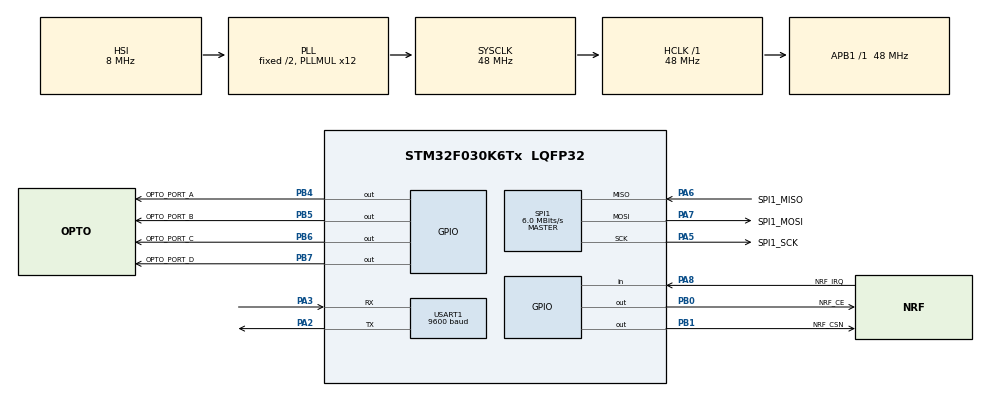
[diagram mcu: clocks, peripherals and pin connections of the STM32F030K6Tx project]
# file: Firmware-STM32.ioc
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Mcu.Family=STM32F0
Mcu.Name=STM32F030K6Tx
Mcu.Package=LQFP32
PA13.Mode=Serial_Wire
PA13.Signal=SYS_SWDIO
PA14.Mode=Serial_Wire
PA14.Signal=SYS_SWCLK
PA2.Mode=Asynchronous
PA2.Signal=USART1_TX
PA3.Mode=Asynchronous
PA3.Signal=USART1_RX
PA5.GPIO_Label=SPI1_SCK
PA5.Mode=Full_Duplex_Master
PA5.Signal=SPI1_SCK
PA6.GPIO_Label=SPI1_MISO
PA6.Mode=Full_Duplex_Master
PA6.Signal=SPI1_MISO
PA7.GPIO_Label=SPI1_MOSI
PA7.Mode=Full_Duplex_Master
PA7.Signal=SPI1_MOSI
PA8.GPIO_Label=NRF_IRQ
PA8.GPIO_PuPd=GPIO_PULLUP
PA8.Signal=GPIO_Input
PB0.GPIO_Label=NRF_CE
PB0.GPIO_ModeDefaultOutputPP=GPIO_MODE_OUTPUT_PP
PB0.GPIO_PuPd=GPIO_NOPULL
PB0.GPIO_Speed=GPIO_SPEED_FREQ_LOW
PB0.PinState=GPIO_PIN_RESET
PB0.Signal=GPIO_Output
PB1.GPIO_Label=NRF_CSN
PB1.GPIO_ModeDefaultOutputPP=GPIO_MODE_OUTPUT_PP
PB1.GPIO_PuPd=GPIO_NOPULL
PB1.GPIO_Speed=GPIO_SPEED_FREQ_LOW
PB1.PinState=GPIO_PIN_RESET
PB1.Signal=GPIO_Output
PB4.GPIO_Label=OPTO_PORT_A
PB4.GPIO_ModeDefaultOutputPP=GPIO_MODE_OUTPUT_PP
PB4.GPIO_PuPd=GPIO_NOPULL
PB4.GPIO_Speed=GPIO_SPEED_FREQ_LOW
PB4.PinState=GPIO_PIN_RESET
PB4.Signal=GPIO_Output
PB5.GPIO_Label=OPTO_PORT_B
PB5.GPIO_ModeDefaultOutputPP=GPIO_MODE_OUTPUT_PP
PB5.GPIO_PuPd=GPIO_NOPULL
PB5.GPIO_Speed=GPIO_SPEED_FREQ_LOW
PB5.PinState=GPIO_PIN_RESET
PB5.Signal=GPIO_Output
PB6.GPIO_FM6=__NULL
PB6.GPIO_Label=OPTO_PORT_C
PB6.GPIO_ModeDefaultOutputPP=GPIO_MODE_OUTPUT_PP
PB6.GPIO_PuPd=GPIO_NOPULL
PB6.GPIO_Speed=GPIO_SPEED_FREQ_LOW
PB6.PinState=GPIO_PIN_RESET
PB6.Signal=GPIO_Output
PB7.GPIO_FM7=__NULL
PB7.GPIO_Label=OPTO_PORT_D
PB7.GPIO_ModeDefaultOutputPP=GPIO_MODE_OUTPUT_PP
PB7.GPIO_PuPd=GPIO_NOPULL
PB7.GPIO_Speed=GPIO_SPEED_FREQ_LOW
PB7.PinState=GPIO_PIN_RESET
PB7.Signal=GPIO_Output
ProjectManager.HeapSize=0x200
ProjectManager.StackSize=0x400
ProjectManager.TargetToolchain=TrueSTUDIO
RCC.AHBFreq_Value=48000000
RCC.APB1Freq_Value=48000000
RCC.APB1TimFreq_Value=48000000
RCC.HCLKFreq_Value=48000000
RCC.PLLMUL=RCC_PLL_MUL12
RCC.SYSCLKFreq_VALUE=48000000
RCC.SYSCLKSource=RCC_SYSCLKSOURCE_PLLCLK
SPI1.BaudRatePrescaler=SPI_BAUDRATEPRESCALER_8
SPI1.CalculateBaudRate=6.0 MBits/s
SPI1.DataSize=SPI_DATASIZE_8BIT
SPI1.Direction=SPI_DIRECTION_2LINES
SPI1.Mode=SPI_MODE_MASTER
SPI1.NSSPMode=SPI_NSS_PULSE_DISABLE
SPI1.VirtualType=VM_MASTER
USART1.BaudRate=9600
USART1.VirtualMode-Asynchronous=VM_ASYNC
board=Firmware-STM32

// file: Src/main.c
/**
  ******************************************************************************
  * @file           : main.c
  * @brief          : Main program body
  ******************************************************************************
  ** This notice applies to any and all portions of this file
  * that are not between comment pairs USER CODE BEGIN and
  * USER CODE END. Other portions of this file, whether
  * inserted by the user or by software development tools
  * are owned by their respective copyright owners.
  *
  * COPYRIGHT(c) 2018 STMicroelectronics
  *
  * Redistribution and use in source and binary forms, with or without modification,
  * are permitted provided that the following conditions are met:
  *   1. Redistributions of source code must retain the above copyright notice,
  *      this list of conditions and the following disclaimer.
  *   2. Redistributions in binary form must reproduce the above copyright notice,
  *      this list of conditions and the following disclaimer in the documentation
  *      and/or other materials provided with the distribution.
  *   3. Neither the name of STMicroelectronics nor the names of its contributors
  *      may be used to endorse or promote products derived from this software
  *      without specific prior written permission.
  *
  * THIS SOFTWARE IS PROVIDED BY THE COPYRIGHT HOLDERS AND CONTRIBUTORS "AS IS"
  * AND ANY EXPRESS OR IMPLIED WARRANTIES, INCLUDING, BUT NOT LIMITED TO, THE
  * IMPLIED WARRANTIES OF MERCHANTABILITY AND FITNESS FOR A PARTICULAR PURPOSE ARE
  * DISCLAIMED. IN NO EVENT SHALL THE COPYRIGHT HOLDER OR CONTRIBUTORS BE LIABLE
  * FOR ANY DIRECT, INDIRECT, INCIDENTAL, SPECIAL, EXEMPLARY, OR CONSEQUENTIAL
  * DAMAGES (INCLUDING, BUT NOT LIMITED TO, PROCUREMENT OF SUBSTITUTE GOODS OR
  * SERVICES; LOSS OF USE, DATA, OR PROFITS; OR BUSINESS INTERRUPTION) HOWEVER
  * CAUSED AND ON ANY THEORY OF LIABILITY, WHETHER IN CONTRACT, STRICT LIABILITY,
  * OR TORT (INCLUDING NEGLIGENCE OR OTHERWISE) ARISING IN ANY WAY OUT OF THE USE
  * OF THIS SOFTWARE, EVEN IF ADVISED OF THE POSSIBILITY OF SUCH DAMAGE.
  *
  ******************************************************************************
  */
#include "main.h"
#include "stm32f0xx_hal.h"

/* USER CODE BEGIN Includes */
#include "receiver.h"

#include  <errno.h>
#include  <sys/unistd.h>
/* USER CODE END Includes */

SPI_HandleTypeDef hspi1;

UART_HandleTypeDef huart1;

/* USER CODE BEGIN PV */
/* Private variables ---------------------------------------------------------*/

/* USER CODE END PV */

void SystemClock_Config(void);
static void MX_GPIO_Init(void);
static void MX_SPI1_Init(void);
static void MX_USART1_UART_Init(void);

/* USER CODE BEGIN PFP */
/* Private function prototypes -----------------------------------------------*/

/* USER CODE END PFP */

/* USER CODE BEGIN 0 */

int _write(int fd, const void* data, size_t len)
{
   if ((fd != STDOUT_FILENO) && (fd != STDERR_FILENO))
   {
      errno = EBADF;
      return -1;
   }

   HAL_StatusTypeDef status = HAL_UART_Transmit(&huart1, (uint8_t*)data, len, 1000);

   return (status == HAL_OK ? len : 0);
}

/* USER CODE END 0 */

int main(void)
{

  /* MCU Configuration----------------------------------------------------------*/

  /* Reset of all peripherals, Initializes the Flash interface and the Systick. */
  HAL_Init();

  /* Configure the system clock */
  SystemClock_Config();

  /* Initialize all configured peripherals */
  MX_GPIO_Init();
  MX_SPI1_Init();
  MX_USART1_UART_Init();
  /* USER CODE BEGIN 2 */

  receiver_init(&hspi1);

  /* USER CODE END 2 */

  /* Infinite loop */
  /* USER CODE BEGIN WHILE */
  while (1)
  {
      receiver_task();
  /* USER CODE END WHILE */

  }

}

void SystemClock_Config(void)
{

  RCC_OscInitTypeDef RCC_OscInitStruct;
  RCC_ClkInitTypeDef RCC_ClkInitStruct;
  RCC_PeriphCLKInitTypeDef PeriphClkInit;

    /**Initializes the CPU, AHB and APB busses clocks
    */
  RCC_OscInitStruct.OscillatorType = RCC_OSCILLATORTYPE_HSI;
  RCC_OscInitStruct.HSIState = RCC_HSI_ON;
  RCC_OscInitStruct.HSICalibrationValue = 16;
  RCC_OscInitStruct.PLL.PLLState = RCC_PLL_ON;
  RCC_OscInitStruct.PLL.PLLSource = RCC_PLLSOURCE_HSI;
  RCC_OscInitStruct.PLL.PLLMUL = RCC_PLL_MUL12;
  RCC_OscInitStruct.PLL.PREDIV = RCC_PREDIV_DIV1;
  if (HAL_RCC_OscConfig(&RCC_OscInitStruct) != HAL_OK)
  {
    _Error_Handler(__FILE__, __LINE__);
  }

    /**Initializes the CPU, AHB and APB busses clocks
    */
  RCC_ClkInitStruct.ClockType = RCC_CLOCKTYPE_HCLK|RCC_CLOCKTYPE_SYSCLK
                              |RCC_CLOCKTYPE_PCLK1;
  RCC_ClkInitStruct.SYSCLKSource = RCC_SYSCLKSOURCE_PLLCLK;
  RCC_ClkInitStruct.AHBCLKDivider = RCC_SYSCLK_DIV1;
  RCC_ClkInitStruct.APB1CLKDivider = RCC_HCLK_DIV1;

  if (HAL_RCC_ClockConfig(&RCC_ClkInitStruct, FLASH_LATENCY_1) != HAL_OK)
  {
    _Error_Handler(__FILE__, __LINE__);
  }

  PeriphClkInit.PeriphClockSelection = RCC_PERIPHCLK_USART1;
  PeriphClkInit.Usart1ClockSelection = RCC_USART1CLKSOURCE_PCLK1;
  if (HAL_RCCEx_PeriphCLKConfig(&PeriphClkInit) != HAL_OK)
  {
    _Error_Handler(__FILE__, __LINE__);
  }

    /**Configure the Systick interrupt time
    */
  HAL_SYSTICK_Config(HAL_RCC_GetHCLKFreq()/1000);

    /**Configure the Systick
    */
  HAL_SYSTICK_CLKSourceConfig(SYSTICK_CLKSOURCE_HCLK);

  /* SysTick_IRQn interrupt configuration */
  HAL_NVIC_SetPriority(SysTick_IRQn, 0, 0);
}

/* SPI1 init function */
static void MX_SPI1_Init(void)
{

  /* SPI1 parameter configuration*/
  hspi1.Instance = SPI1;
  hspi1.Init.Mode = SPI_MODE_MASTER;
  hspi1.Init.Direction = SPI_DIRECTION_2LINES;
  hspi1.Init.DataSize = SPI_DATASIZE_8BIT;
  hspi1.Init.CLKPolarity = SPI_POLARITY_LOW;
  hspi1.Init.CLKPhase = SPI_PHASE_1EDGE;
  hspi1.Init.NSS = SPI_NSS_SOFT;
  hspi1.Init.BaudRatePrescaler = SPI_BAUDRATEPRESCALER_8;
  hspi1.Init.FirstBit = SPI_FIRSTBIT_MSB;
  hspi1.Init.TIMode = SPI_TIMODE_DISABLE;
  hspi1.Init.CRCCalculation = SPI_CRCCALCULATION_DISABLE;
  hspi1.Init.CRCPolynomial = 7;
  hspi1.Init.CRCLength = SPI_CRC_LENGTH_DATASIZE;
  hspi1.Init.NSSPMode = SPI_NSS_PULSE_DISABLE;
  if (HAL_SPI_Init(&hspi1) != HAL_OK)
  {
    _Error_Handler(__FILE__, __LINE__);
  }

}

/* USART1 init function */
static void MX_USART1_UART_Init(void)
{

  huart1.Instance = USART1;
  huart1.Init.BaudRate = 9600;
  huart1.Init.WordLength = UART_WORDLENGTH_8B;
  huart1.Init.StopBits = UART_STOPBITS_1;
  huart1.Init.Parity = UART_PARITY_NONE;
  huart1.Init.Mode = UART_MODE_TX_RX;
  huart1.Init.HwFlowCtl = UART_HWCONTROL_NONE;
  huart1.Init.OverSampling = UART_OVERSAMPLING_16;
  huart1.Init.OneBitSampling = UART_ONE_BIT_SAMPLE_DISABLE;
  huart1.AdvancedInit.AdvFeatureInit = UART_ADVFEATURE_NO_INIT;
  if (HAL_UART_Init(&huart1) != HAL_OK)
  {
    _Error_Handler(__FILE__, __LINE__);
  }

}

/** Configure pins as
        * Analog
        * Input
        * Output
        * EVENT_OUT
        * EXTI
        * Free pins are configured automatically as Analog (this feature is enabled through
        * the Code Generation settings)
*/
static void MX_GPIO_Init(void)
{

  GPIO_InitTypeDef GPIO_InitStruct;

  /* GPIO Ports Clock Enable */
  __HAL_RCC_GPIOF_CLK_ENABLE();
  __HAL_RCC_GPIOA_CLK_ENABLE();
  __HAL_RCC_GPIOB_CLK_ENABLE();

  /*Configure GPIO pin Output Level */
  HAL_GPIO_WritePin(GPIOB, NRF_CE_Pin|NRF_CSN_Pin|OPTO_PORT_A_Pin|OPTO_PORT_B_Pin
                          |OPTO_PORT_C_Pin|OPTO_PORT_D_Pin, GPIO_PIN_RESET);

  /*Configure GPIO pins : PF0 PF1 */
  GPIO_InitStruct.Pin = GPIO_PIN_0|GPIO_PIN_1;
  GPIO_InitStruct.Mode = GPIO_MODE_ANALOG;
  GPIO_InitStruct.Pull = GPIO_NOPULL;
  HAL_GPIO_Init(GPIOF, &GPIO_InitStruct);

  /*Configure GPIO pins : PA0 PA1 PA4 PA9
                           PA10 PA11 PA12 PA15 */
  GPIO_InitStruct.Pin = GPIO_PIN_0|GPIO_PIN_1|GPIO_PIN_4|GPIO_PIN_9
                          |GPIO_PIN_10|GPIO_PIN_11|GPIO_PIN_12|GPIO_PIN_15;
  GPIO_InitStruct.Mode = GPIO_MODE_ANALOG;
  GPIO_InitStruct.Pull = GPIO_NOPULL;
  HAL_GPIO_Init(GPIOA, &GPIO_InitStruct);

  /*Configure GPIO pins : NRF_CE_Pin NRF_CSN_Pin OPTO_PORT_A_Pin OPTO_PORT_B_Pin
                           OPTO_PORT_C_Pin OPTO_PORT_D_Pin */
  GPIO_InitStruct.Pin = NRF_CE_Pin|NRF_CSN_Pin|OPTO_PORT_A_Pin|OPTO_PORT_B_Pin
                          |OPTO_PORT_C_Pin|OPTO_PORT_D_Pin;
  GPIO_InitStruct.Mode = GPIO_MODE_OUTPUT_PP;
  GPIO_InitStruct.Pull = GPIO_NOPULL;
  GPIO_InitStruct.Speed = GPIO_SPEED_FREQ_LOW;
  HAL_GPIO_Init(GPIOB, &GPIO_InitStruct);

  /*Configure GPIO pin : NRF_IRQ_Pin */
  GPIO_InitStruct.Pin = NRF_IRQ_Pin;
  GPIO_InitStruct.Mode = GPIO_MODE_INPUT;
  GPIO_InitStruct.Pull = GPIO_PULLUP;
  HAL_GPIO_Init(NRF_IRQ_GPIO_Port, &GPIO_InitStruct);

  /*Configure GPIO pin : PB3 */
  GPIO_InitStruct.Pin = GPIO_PIN_3;
  GPIO_InitStruct.Mode = GPIO_MODE_ANALOG;
  GPIO_InitStruct.Pull = GPIO_NOPULL;
  HAL_GPIO_Init(GPIOB, &GPIO_InitStruct);

}

void _Error_Handler(char *file, int line)
{
  while(1)
  {
  }
}

/************************ (C) COPYRIGHT STMicroelectronics *****END OF FILE****/
